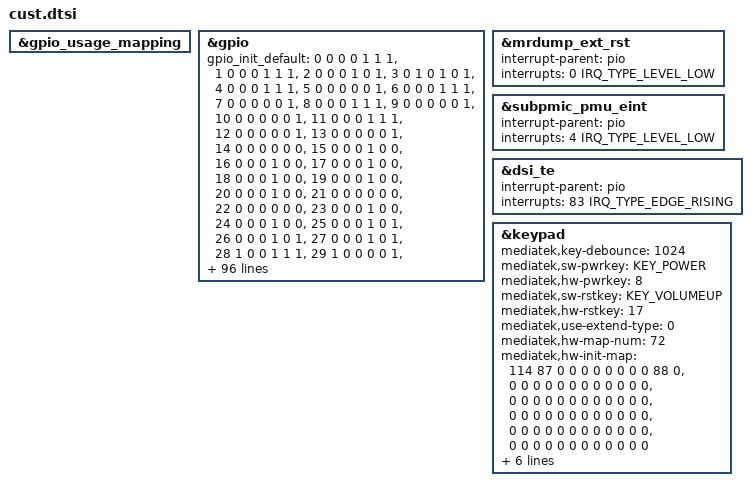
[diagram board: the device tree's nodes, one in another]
// SPDX-License-Identifier: (GPL-2.0 OR MIT)

&gpio_usage_mapping {
};

&gpio {
	gpio_init_default =
		<0 0 0 0 1 1 1>,
		<1 0 0 0 1 1 1>,
		<2 0 0 0 1 0 1>,
		<3 0 1 0 1 0 1>,
		<4 0 0 0 1 1 1>,
		<5 0 0 0 0 0 1>,
		<6 0 0 0 1 1 1>,
		<7 0 0 0 0 0 1>,
		<8 0 0 0 1 1 1>,
		<9 0 0 0 0 0 1>,
		<10 0 0 0 0 0 1>,
		<11 0 0 0 1 1 1>,
		<12 0 0 0 0 0 1>,
		<13 0 0 0 0 0 1>,
		<14 0 0 0 0 0 0>,
		<15 0 0 0 1 0 0>,
		<16 0 0 0 1 0 0>,
		<17 0 0 0 1 0 0>,
		<18 0 0 0 1 0 0>,
		<19 0 0 0 1 0 0>,
		<20 0 0 0 1 0 0>,
		<21 0 0 0 0 0 0>,
		<22 0 0 0 0 0 0>,
		<23 0 0 0 1 0 0>,
		<24 0 0 0 1 0 0>,
		<25 0 0 0 1 0 1>,
		<26 0 0 0 1 0 1>,
		<27 0 0 0 1 0 1>,
		<28 1 0 0 1 1 1>,
		<29 1 0 0 0 0 1>,
		<30 1 0 0 0 0 1>,
		<31 1 0 0 0 0 1>,
		<32 1 0 0 0 0 1>,
		<33 1 0 0 1 0 1>,
		<34 0 0 0 1 0 0>,
		<35 0 0 0 1 0 0>,
		<36 0 0 0 1 0 0>,
		<37 0 0 0 1 0 0>,
		<38 0 1 0 1 0 1>,
		<39 0 1 0 1 0 1>,
		<40 0 1 0 1 0 1>,
		<41 0 1 0 1 0 1>,
		<42 0 0 0 1 0 0>,
		<43 0 0 0 1 0 0>,
		<44 0 0 0 1 0 0>,
		<45 0 0 0 1 0 0>,
		<46 4 0 0 1 0 0>,
		<47 4 0 0 1 0 0>,
		<48 4 0 0 0 0 0>,
		<49 4 0 0 1 0 0>,
		<50 0 0 0 0 0 1>,
		<51 0 0 0 0 0 1>,
		<52 0 0 0 0 0 1>,
		<53 0 0 0 0 0 1>,
		<54 0 0 0 1 0 1>,
		<55 1 0 0 0 0 1>,
		<56 1 0 0 0 0 1>,
		<57 0 0 0 1 0 1>,
		<58 1 0 0 0 0 1>,
		<59 1 0 0 0 0 1>,
		<60 1 0 0 0 0 1>,
		<61 1 0 0 0 0 1>,
		<62 0 0 0 1 0 1>,
		<63 0 0 0 1 0 1>,
		<64 0 0 0 1 0 1>,
		<65 0 0 0 1 0 1>,
		<66 1 0 0 1 1 1>,
		<67 1 0 0 1 1 1>,
		<68 1 0 0 1 0 1>,
		<69 1 0 0 1 0 1>,
		<70 1 0 0 1 0 1>,
		<71 1 0 0 0 0 1>,
		<72 1 0 0 0 0 1>,
		<73 1 0 0 0 0 1>,
		<74 1 0 0 0 0 1>,
		<75 1 0 0 0 0 1>,
		<76 1 0 0 0 0 1>,
		<77 0 0 0 1 0 1>,
		<78 0 0 0 1 0 1>,
		<79 0 0 0 1 0 1>,
		<80 0 0 0 1 0 1>,
		<81 0 0 0 1 0 1>,
		<82 0 0 0 1 0 1>,
		<83 1 0 0 1 0 1>,
		<84 0 1 0 1 0 1>,
		<85 0 1 0 1 0 1>,
		<86 0 1 1 1 0 0>,
		<87 0 1 0 1 0 0>,
		<88 0 1 0 1 0 0>,
		<89 0 1 0 1 0 0>,
		<90 0 1 0 1 0 0>,
		<91 0 1 0 1 0 0>,
		<92 0 0 0 1 0 0>,
		<93 0 0 0 0 0 0>,
		<94 0 0 0 1 0 0>,
		<95 0 1 0 1 0 0>,
		<96 0 0 0 1 0 0>,
		<97 0 0 0 1 0 0>,
		<98 0 1 0 1 0 0>,
		<99 0 1 0 1 0 0>,
		<100 0 0 0 0 0 0>,
		<101 0 0 0 0 0 0>,
		<102 0 0 0 1 0 0>,
		<103 0 0 0 1 0 0>,
		<104 0 0 0 1 0 0>,
		<105 0 0 0 1 0 0>,
		<106 0 0 0 0 0 0>,
		<107 0 0 0 1 0 0>,
		<108 0 0 0 1 0 0>,
		<109 0 0 0 1 0 0>,
		<110 0 0 0 1 0 0>,
		<111 0 0 0 1 0 0>,
		<112 0 0 0 1 0 0>,
		<113 0 0 0 1 0 0>,
		<114 0 0 0 1 0 0>,
		<115 0 0 0 1 0 0>,
		<116 0 0 0 1 0 0>,
		<117 0 0 0 1 0 0>,
		<118 0 0 0 1 0 0>,
		<119 0 0 0 1 0 0>,
		<120 0 0 0 1 0 0>,
		<121 0 0 0 1 0 0>,
		<122 0 0 0 1 0 0>,
		<123 0 0 0 1 0 0>,
		<124 0 0 0 1 0 0>,
		<125 0 0 0 1 0 0>,
		<126 0 0 0 1 0 0>,
		<127 0 0 0 1 0 0>,
		<128 0 0 0 1 0 0>,
		<129 0 0 0 1 0 0>,
		<130 1 0 0 0 1 1>,
		<131 1 0 0 0 1 1>,
		<132 2 0 0 1 1 0>,
		<133 2 0 0 1 1 0>,
		<134 1 0 0 1 1 1>,
		<135 1 0 0 1 1 1>,
		<136 0 0 0 1 0 1>,
		<137 0 0 0 1 0 1>,
		<138 0 0 0 1 0 1>,
		<139 0 0 0 1 0 1>,
		<140 1 0 0 1 1 1>,
		<141 1 0 0 1 1 1>,
		<142 2 0 0 1 1 1>,
		<143 2 0 0 1 1 1>,
		<144 1 0 0 1 1 1>,
		<145 1 0 0 1 1 1>,
		<146 1 0 0 1 1 1>,
		<147 1 0 0 1 1 1>,
		<148 1 0 0 0 1 1>,
		<149 1 0 0 0 1 1>,
		<150 0 1 0 1 0 1>,
		<151 0 1 1 1 0 1>,
		<152 0 1 0 1 0 1>,
		<153 0 1 0 1 0 1>,
		<154 0 1 0 1 0 1>,
		<155 0 1 0 1 0 1>,
		<156 0 1 0 1 0 1>,
		<157 0 1 0 1 0 1>,
		<158 0 1 0 1 0 0>,
		<159 0 1 0 1 0 0>,
		<160 1 0 0 0 0 1>,
		<161 1 0 0 0 0 1>,
		<162 1 0 0 0 0 1>,
		<163 1 0 0 1 0 1>,
		<164 1 0 0 0 0 1>,
		<165 1 0 0 0 0 1>,
		<166 1 0 0 0 0 1>,
		<167 1 0 0 1 0 1>,
		<168 1 0 0 0 0 0>,
		<169 1 0 0 0 0 1>,
		<170 1 0 0 0 0 1>,
		<171 1 0 0 0 0 1>,
		<172 1 0 0 0 0 1>,
		<173 1 0 0 1 0 1>,
		<174 1 0 0 1 0 1>,
		<175 1 0 0 1 0 1>,
		<176 1 0 0 1 0 1>,
		<177 0 0 0 1 0 0>,
		<178 0 0 0 1 0 0>,
		<179 0 0 0 1 0 0>,
		<180 0 0 0 1 0 0>,
		<181 0 0 0 1 0 0>,
		<182 0 0 0 1 0 0>,
		<183 0 0 0 1 0 0>,
		<184 0 0 0 1 0 0>,
		<185 0 0 0 1 0 0>,
		<186 0 0 0 1 0 1>,
		<187 0 0 0 1 0 1>,
		<188 0 0 0 1 0 0>,
		<189 0 0 0 1 0 0>,
		<190 0 0 0 1 0 0>,
		<191 0 0 0 1 0 0>,
		<192 0 0 0 1 0 0>,
		<193 0 0 0 1 0 0>,
		<194 0 0 0 1 0 0>,
		<195 0 0 0 1 0 0>,
		<196 0 0 0 1 0 0>,
		<197 0 0 0 1 0 0>,
		<198 0 0 0 1 0 0>,
		<199 0 0 0 1 0 0>,
		<200 0 0 0 1 0 0>,
		<201 0 0 0 1 0 0>,
		<202 0 0 0 1 0 0>,
		<203 0 0 0 1 0 0>,
		<204 0 0 0 1 0 0>,
		<205 0 0 0 1 0 0>,
		<206 0 0 0 1 0 0>,
		<207 0 0 0 1 0 0>,
		<208 0 0 0 1 0 0>,
		<209 0 0 0 1 0 0>,
		<210 0 0 0 1 0 0>,
		<211 0 0 0 1 0 0>,
		<212 0 0 0 1 0 0>,
		<213 0 0 0 1 0 0>,
		<214 0 0 0 1 0 0>,
		<215 0 0 0 1 0 0>,
		<216 0 0 0 1 0 0>,
		<217 0 0 0 1 0 0>,
		<218 0 0 0 1 0 0>,
		<219 0 0 0 1 0 0>,
		<220 0 0 0 1 0 0>,
		<221 0 0 0 1 0 0>;
};

&mrdump_ext_rst {
	interrupt-parent = <&pio>;
	interrupts = <0 IRQ_TYPE_LEVEL_LOW>;
	status = "okay";
};

&subpmic_pmu_eint {
	interrupt-parent = <&pio>;
	interrupts = <4 IRQ_TYPE_LEVEL_LOW>;
	status = "okay";
};

&dsi_te {
	interrupt-parent = <&pio>;
	interrupts = <83 IRQ_TYPE_EDGE_RISING>;
	status = "okay";
};

&keypad {
	mediatek,key-debounce = <1024>;
	mediatek,sw-pwrkey = <KEY_POWER>;
	mediatek,hw-pwrkey = <8>;
	mediatek,sw-rstkey = <KEY_VOLUMEUP>;
	mediatek,hw-rstkey = <17>;
	mediatek,use-extend-type = <0>;
	mediatek,hw-map-num = <72>;
	mediatek,hw-init-map =
		<114 87 0 0 0 0 0 0 0 0 88 0>,
		<0 0 0 0 0 0 0 0 0 0 0 0>,
		<0 0 0 0 0 0 0 0 0 0 0 0>,
		<0 0 0 0 0 0 0 0 0 0 0 0>,
		<0 0 0 0 0 0 0 0 0 0 0 0>,
		<0 0 0 0 0 0 0 0 0 0 0 0>;
	mediatek,pwrkey-eint-gpio = <0>;
	mediatek,pwkey-gpio-din = <0>;
	mediatek,hw-dl-key0 = <17>;
	mediatek,hw-dl-key1 = <0>;
	mediatek,hw-dl-key2 = <8>;
	mediatek,hw-recovery-key = <17>;
	status = "okay";
};
